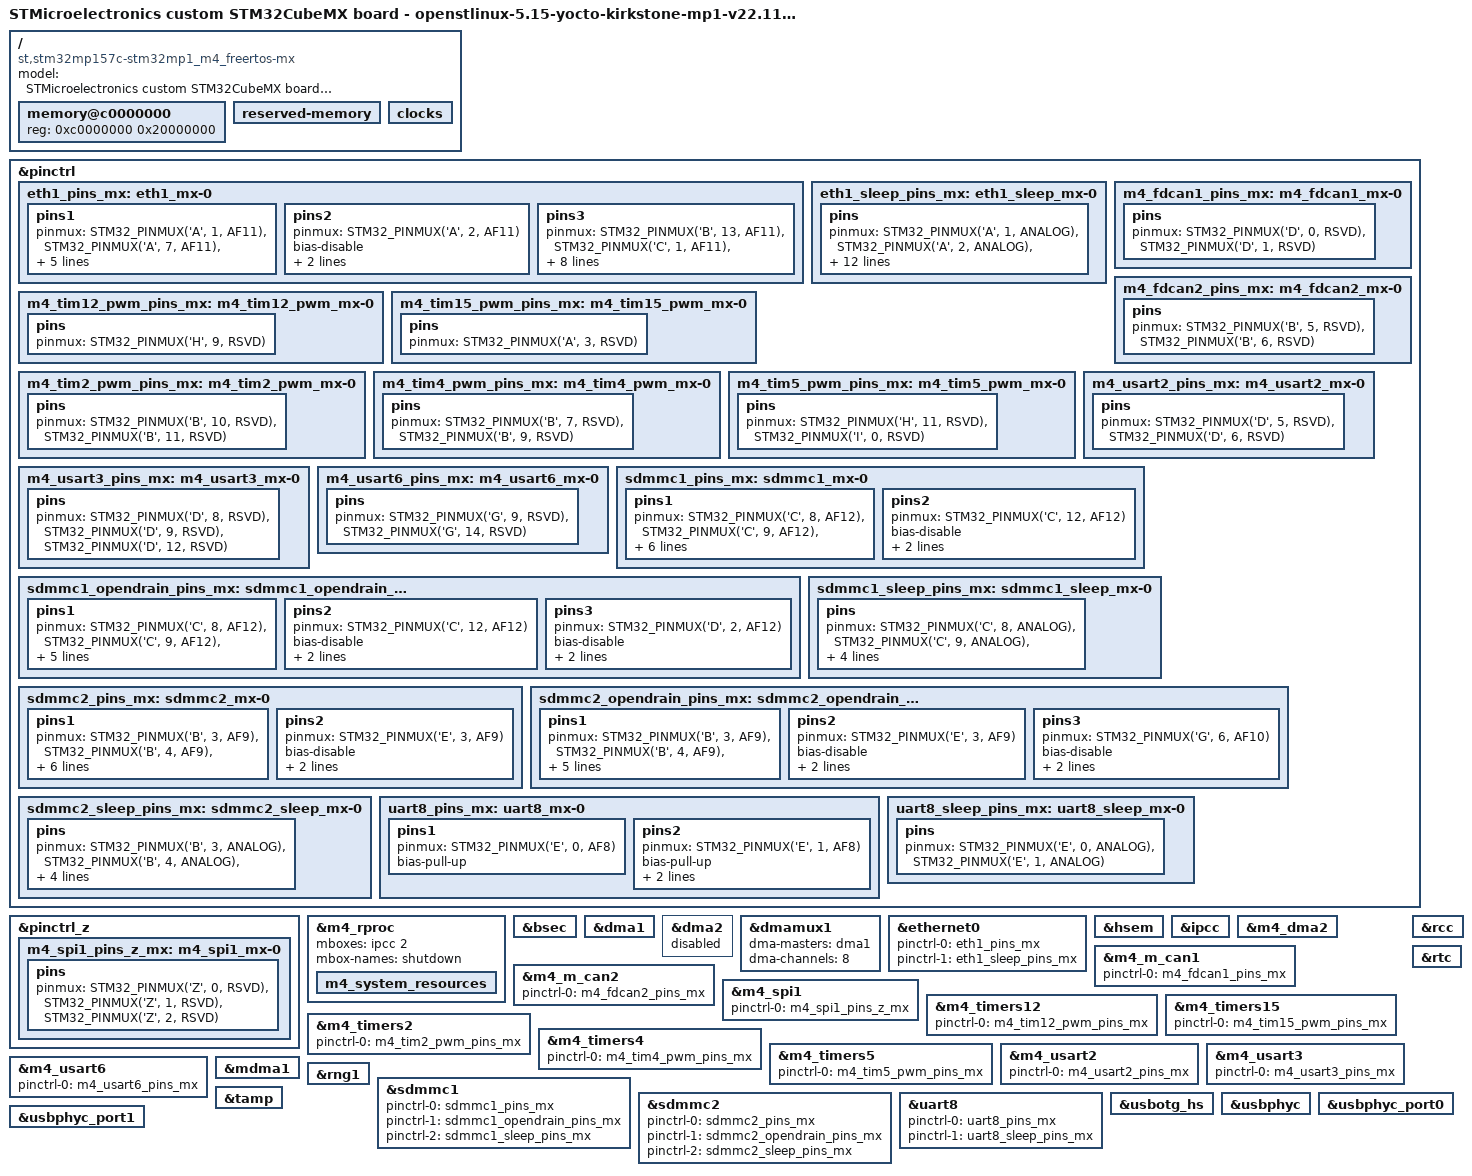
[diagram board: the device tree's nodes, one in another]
/* SPDX-License-Identifier: (GPL-2.0+ OR BSD-3-Clause) */
/*
 * Copyright (C) STMicroelectronics 2023 - All Rights Reserved
 * Author: STM32CubeMX code generation for STMicroelectronics.
 */

/* For more information on Device Tree configuration, please refer to
 * https://wiki.st.com/stm32mpu/wiki/Category:Device_tree_configuration
 */

/dts-v1/;
#include <dt-bindings/pinctrl/stm32-pinfunc.h>

#include "stm32mp157.dtsi"
#include "stm32mp15xc.dtsi"
#include "stm32mp15xxac-pinctrl.dtsi"
#include "stm32mp15-m4-srm.dtsi"

/* USER CODE BEGIN includes */
/* USER CODE END includes */

/ {
	model = "STMicroelectronics custom STM32CubeMX board - openstlinux-5.15-yocto-kirkstone-mp1-v22.11.23";
	compatible = "st,stm32mp157c-stm32mp1_m4_freertos-mx", "st,stm32mp157";

	memory@c0000000 {
		device_type = "memory";
		reg = <0xc0000000 0x20000000>;

		/* USER CODE BEGIN memory */
		/* USER CODE END memory */
	};

	reserved-memory {
		#address-cells = <1>;
		#size-cells = <1>;
		ranges;

		/* USER CODE BEGIN reserved-memory */
		/* USER CODE END reserved-memory */
	};

	/* USER CODE BEGIN root */
	/* USER CODE END root */

	clocks {

		/* USER CODE BEGIN clocks */
		/* USER CODE END clocks */
	};

}; /*root*/

&pinctrl {

	eth1_pins_mx: eth1_mx-0 {
		pins1 {
			pinmux = <STM32_PINMUX('A', 1, AF11)>, /* ETH1_RX_CLK */
					 <STM32_PINMUX('A', 7, AF11)>, /* ETH1_RX_CTL */
					 <STM32_PINMUX('C', 4, AF11)>, /* ETH1_RXD0 */
					 <STM32_PINMUX('C', 5, AF11)>, /* ETH1_RXD1 */
					 <STM32_PINMUX('H', 6, AF11)>, /* ETH1_RXD2 */
					 <STM32_PINMUX('H', 7, AF11)>; /* ETH1_RXD3 */
			bias-disable;
		};
		pins2 {
			pinmux = <STM32_PINMUX('A', 2, AF11)>; /* ETH1_MDIO */
			bias-disable;
			drive-push-pull;
			slew-rate = <0>;
		};
		pins3 {
			pinmux = <STM32_PINMUX('B', 13, AF11)>, /* ETH1_TXD1 */
					 <STM32_PINMUX('C', 1, AF11)>, /* ETH1_MDC */
					 <STM32_PINMUX('C', 2, AF11)>, /* ETH1_TXD2 */
					 <STM32_PINMUX('E', 2, AF11)>, /* ETH1_TXD3 */
					 <STM32_PINMUX('G', 4, AF11)>, /* ETH1_GTX_CLK */
					 <STM32_PINMUX('G', 11, AF11)>, /* ETH1_TX_CTL */
					 <STM32_PINMUX('G', 13, AF11)>; /* ETH1_TXD0 */
			bias-disable;
			drive-push-pull;
			slew-rate = <2>;
		};
	};

	eth1_sleep_pins_mx: eth1_sleep_mx-0 {
		pins {
			pinmux = <STM32_PINMUX('A', 1, ANALOG)>, /* ETH1_RX_CLK */
					 <STM32_PINMUX('A', 2, ANALOG)>, /* ETH1_MDIO */
					 <STM32_PINMUX('A', 7, ANALOG)>, /* ETH1_RX_CTL */
					 <STM32_PINMUX('B', 13, ANALOG)>, /* ETH1_TXD1 */
					 <STM32_PINMUX('C', 1, ANALOG)>, /* ETH1_MDC */
					 <STM32_PINMUX('C', 2, ANALOG)>, /* ETH1_TXD2 */
					 <STM32_PINMUX('C', 4, ANALOG)>, /* ETH1_RXD0 */
					 <STM32_PINMUX('C', 5, ANALOG)>, /* ETH1_RXD1 */
					 <STM32_PINMUX('E', 2, ANALOG)>, /* ETH1_TXD3 */
					 <STM32_PINMUX('G', 4, ANALOG)>, /* ETH1_GTX_CLK */
					 <STM32_PINMUX('G', 11, ANALOG)>, /* ETH1_TX_CTL */
					 <STM32_PINMUX('G', 13, ANALOG)>, /* ETH1_TXD0 */
					 <STM32_PINMUX('H', 6, ANALOG)>, /* ETH1_RXD2 */
					 <STM32_PINMUX('H', 7, ANALOG)>; /* ETH1_RXD3 */
		};
	};

	m4_fdcan1_pins_mx: m4_fdcan1_mx-0 {
		pins {
			pinmux = <STM32_PINMUX('D', 0, RSVD)>, /* FDCAN1_RX */
					 <STM32_PINMUX('D', 1, RSVD)>; /* FDCAN1_TX */
		};
	};

	m4_fdcan2_pins_mx: m4_fdcan2_mx-0 {
		pins {
			pinmux = <STM32_PINMUX('B', 5, RSVD)>, /* FDCAN2_RX */
					 <STM32_PINMUX('B', 6, RSVD)>; /* FDCAN2_TX */
		};
	};

	m4_tim12_pwm_pins_mx: m4_tim12_pwm_mx-0 {
		pins {
			pinmux = <STM32_PINMUX('H', 9, RSVD)>; /* TIM12_CH2 */
		};
	};

	m4_tim15_pwm_pins_mx: m4_tim15_pwm_mx-0 {
		pins {
			pinmux = <STM32_PINMUX('A', 3, RSVD)>; /* TIM15_CH2 */
		};
	};

	m4_tim2_pwm_pins_mx: m4_tim2_pwm_mx-0 {
		pins {
			pinmux = <STM32_PINMUX('B', 10, RSVD)>, /* TIM2_CH3 */
					 <STM32_PINMUX('B', 11, RSVD)>; /* TIM2_CH4 */
		};
	};

	m4_tim4_pwm_pins_mx: m4_tim4_pwm_mx-0 {
		pins {
			pinmux = <STM32_PINMUX('B', 7, RSVD)>, /* TIM4_CH2 */
					 <STM32_PINMUX('B', 9, RSVD)>; /* TIM4_CH4 */
		};
	};

	m4_tim5_pwm_pins_mx: m4_tim5_pwm_mx-0 {
		pins {
			pinmux = <STM32_PINMUX('H', 11, RSVD)>, /* TIM5_CH2 */
					 <STM32_PINMUX('I', 0, RSVD)>; /* TIM5_CH4 */
		};
	};

	m4_usart2_pins_mx: m4_usart2_mx-0 {
		pins {
			pinmux = <STM32_PINMUX('D', 5, RSVD)>, /* USART2_TX */
					 <STM32_PINMUX('D', 6, RSVD)>; /* USART2_RX */
		};
	};

	m4_usart3_pins_mx: m4_usart3_mx-0 {
		pins {
			pinmux = <STM32_PINMUX('D', 8, RSVD)>, /* USART3_TX */
					 <STM32_PINMUX('D', 9, RSVD)>, /* USART3_RX */
					 <STM32_PINMUX('D', 12, RSVD)>; /* USART3_DE */
		};
	};

	m4_usart6_pins_mx: m4_usart6_mx-0 {
		pins {
			pinmux = <STM32_PINMUX('G', 9, RSVD)>, /* USART6_RX */
					 <STM32_PINMUX('G', 14, RSVD)>; /* USART6_TX */
		};
	};

	sdmmc1_pins_mx: sdmmc1_mx-0 {
		pins1 {
			pinmux = <STM32_PINMUX('C', 8, AF12)>, /* SDMMC1_D0 */
					 <STM32_PINMUX('C', 9, AF12)>, /* SDMMC1_D1 */
					 <STM32_PINMUX('C', 10, AF12)>, /* SDMMC1_D2 */
					 <STM32_PINMUX('C', 11, AF12)>, /* SDMMC1_D3 */
					 <STM32_PINMUX('D', 2, AF12)>; /* SDMMC1_CMD */
			bias-disable;
			drive-push-pull;
			slew-rate = <1>;
		};
		pins2 {
			pinmux = <STM32_PINMUX('C', 12, AF12)>; /* SDMMC1_CK */
			bias-disable;
			drive-push-pull;
			slew-rate = <3>;
		};
	};

	sdmmc1_opendrain_pins_mx: sdmmc1_opendrain_mx-0 {
		pins1 {
			pinmux = <STM32_PINMUX('C', 8, AF12)>, /* SDMMC1_D0 */
					 <STM32_PINMUX('C', 9, AF12)>, /* SDMMC1_D1 */
					 <STM32_PINMUX('C', 10, AF12)>, /* SDMMC1_D2 */
					 <STM32_PINMUX('C', 11, AF12)>; /* SDMMC1_D3 */
			bias-disable;
			drive-push-pull;
			slew-rate = <1>;
		};
		pins2 {
			pinmux = <STM32_PINMUX('C', 12, AF12)>; /* SDMMC1_CK */
			bias-disable;
			drive-push-pull;
			slew-rate = <3>;
		};
		pins3 {
			pinmux = <STM32_PINMUX('D', 2, AF12)>; /* SDMMC1_CMD */
			bias-disable;
			drive-open-drain;
			slew-rate = <1>;
		};
	};

	sdmmc1_sleep_pins_mx: sdmmc1_sleep_mx-0 {
		pins {
			pinmux = <STM32_PINMUX('C', 8, ANALOG)>, /* SDMMC1_D0 */
					 <STM32_PINMUX('C', 9, ANALOG)>, /* SDMMC1_D1 */
					 <STM32_PINMUX('C', 10, ANALOG)>, /* SDMMC1_D2 */
					 <STM32_PINMUX('C', 11, ANALOG)>, /* SDMMC1_D3 */
					 <STM32_PINMUX('C', 12, ANALOG)>, /* SDMMC1_CK */
					 <STM32_PINMUX('D', 2, ANALOG)>; /* SDMMC1_CMD */
		};
	};

	sdmmc2_pins_mx: sdmmc2_mx-0 {
		pins1 {
			pinmux = <STM32_PINMUX('B', 3, AF9)>, /* SDMMC2_D2 */
					 <STM32_PINMUX('B', 4, AF9)>, /* SDMMC2_D3 */
					 <STM32_PINMUX('B', 14, AF9)>, /* SDMMC2_D0 */
					 <STM32_PINMUX('B', 15, AF9)>, /* SDMMC2_D1 */
					 <STM32_PINMUX('G', 6, AF10)>; /* SDMMC2_CMD */
			bias-disable;
			drive-push-pull;
			slew-rate = <1>;
		};
		pins2 {
			pinmux = <STM32_PINMUX('E', 3, AF9)>; /* SDMMC2_CK */
			bias-disable;
			drive-push-pull;
			slew-rate = <3>;
		};
	};

	sdmmc2_opendrain_pins_mx: sdmmc2_opendrain_mx-0 {
		pins1 {
			pinmux = <STM32_PINMUX('B', 3, AF9)>, /* SDMMC2_D2 */
					 <STM32_PINMUX('B', 4, AF9)>, /* SDMMC2_D3 */
					 <STM32_PINMUX('B', 14, AF9)>, /* SDMMC2_D0 */
					 <STM32_PINMUX('B', 15, AF9)>; /* SDMMC2_D1 */
			bias-disable;
			drive-push-pull;
			slew-rate = <1>;
		};
		pins2 {
			pinmux = <STM32_PINMUX('E', 3, AF9)>; /* SDMMC2_CK */
			bias-disable;
			drive-push-pull;
			slew-rate = <3>;
		};
		pins3 {
			pinmux = <STM32_PINMUX('G', 6, AF10)>; /* SDMMC2_CMD */
			bias-disable;
			drive-open-drain;
			slew-rate = <1>;
		};
	};

	sdmmc2_sleep_pins_mx: sdmmc2_sleep_mx-0 {
		pins {
			pinmux = <STM32_PINMUX('B', 3, ANALOG)>, /* SDMMC2_D2 */
					 <STM32_PINMUX('B', 4, ANALOG)>, /* SDMMC2_D3 */
					 <STM32_PINMUX('B', 14, ANALOG)>, /* SDMMC2_D0 */
					 <STM32_PINMUX('B', 15, ANALOG)>, /* SDMMC2_D1 */
					 <STM32_PINMUX('E', 3, ANALOG)>, /* SDMMC2_CK */
					 <STM32_PINMUX('G', 6, ANALOG)>; /* SDMMC2_CMD */
		};
	};

	uart8_pins_mx: uart8_mx-0 {
		pins1 {
			pinmux = <STM32_PINMUX('E', 0, AF8)>; /* UART8_RX */
			bias-pull-up;
		};
		pins2 {
			pinmux = <STM32_PINMUX('E', 1, AF8)>; /* UART8_TX */
			bias-pull-up;
			drive-push-pull;
			slew-rate = <2>;
		};
	};

	uart8_sleep_pins_mx: uart8_sleep_mx-0 {
		pins {
			pinmux = <STM32_PINMUX('E', 0, ANALOG)>, /* UART8_RX */
					 <STM32_PINMUX('E', 1, ANALOG)>; /* UART8_TX */
		};
	};

	/* USER CODE BEGIN pinctrl */
	/* USER CODE END pinctrl */
};

&pinctrl_z {

	m4_spi1_pins_z_mx: m4_spi1_mx-0 {
		pins {
			pinmux = <STM32_PINMUX('Z', 0, RSVD)>, /* SPI1_SCK */
					 <STM32_PINMUX('Z', 1, RSVD)>, /* SPI1_MISO */
					 <STM32_PINMUX('Z', 2, RSVD)>; /* SPI1_MOSI */
		};
	};

	/* USER CODE BEGIN pinctrl_z */
	/* USER CODE END pinctrl_z */
};

&m4_rproc{
	/*Restriction: "memory-region" property is not managed - please to use User-Section if needed*/
	mboxes = <&ipcc 2>;
	mbox-names = "shutdown";
	status = "okay";

	/* USER CODE BEGIN m4_rproc */
	/* USER CODE END m4_rproc */

	m4_system_resources{
		status = "okay";

		/* USER CODE BEGIN m4_system_resources */
		/* USER CODE END m4_system_resources */
	};
};

&bsec{
	status = "okay";

	/* USER CODE BEGIN bsec */
	/* USER CODE END bsec */
};

&dma1{
	status = "okay";

	/* USER CODE BEGIN dma1 */
	/* USER CODE END dma1 */
};

&dma2{
	status = "disabled";

	/* USER CODE BEGIN dma2 */
	/* USER CODE END dma2 */
};

&dmamux1{
	status = "okay";

	dma-masters = <&dma1>;
	dma-channels = <8>;

	/* USER CODE BEGIN dmamux1 */
	/* USER CODE END dmamux1 */
};

&ethernet0{
	pinctrl-names = "default", "sleep";
	pinctrl-0 = <&eth1_pins_mx>;
	pinctrl-1 = <&eth1_sleep_pins_mx>;
	status = "okay";

	/* USER CODE BEGIN ethernet0 */
	/* USER CODE END ethernet0 */
};

&hsem{
	status = "okay";

	/* USER CODE BEGIN hsem */
	/* USER CODE END hsem */
};

&ipcc{
	status = "okay";

	/* USER CODE BEGIN ipcc */
	/* USER CODE END ipcc */
};

&m4_dma2{
	status = "okay";

	/* USER CODE BEGIN m4_dma2 */
	/* USER CODE END m4_dma2 */
};

&m4_m_can1{
	pinctrl-names = "default";
	pinctrl-0 = <&m4_fdcan1_pins_mx>;
	status = "okay";

	/* USER CODE BEGIN m4_m_can1 */
	/* USER CODE END m4_m_can1 */
};

&m4_m_can2{
	pinctrl-names = "default";
	pinctrl-0 = <&m4_fdcan2_pins_mx>;
	status = "okay";

	/* USER CODE BEGIN m4_m_can2 */
	/* USER CODE END m4_m_can2 */
};

&m4_spi1{
	pinctrl-names = "default";
	pinctrl-0 = <&m4_spi1_pins_z_mx>;
	status = "okay";

	/* USER CODE BEGIN m4_spi1 */
	/* USER CODE END m4_spi1 */
};

&m4_timers12{
	pinctrl-names = "default";
	pinctrl-0 = <&m4_tim12_pwm_pins_mx>;
	status = "okay";

	/* USER CODE BEGIN m4_timers12 */
	/* USER CODE END m4_timers12 */
};

&m4_timers15{
	pinctrl-names = "default";
	pinctrl-0 = <&m4_tim15_pwm_pins_mx>;
	status = "okay";

	/* USER CODE BEGIN m4_timers15 */
	/* USER CODE END m4_timers15 */
};

&m4_timers2{
	pinctrl-names = "default";
	pinctrl-0 = <&m4_tim2_pwm_pins_mx>;
	status = "okay";

	/* USER CODE BEGIN m4_timers2 */
	/* USER CODE END m4_timers2 */
};

&m4_timers4{
	pinctrl-names = "default";
	pinctrl-0 = <&m4_tim4_pwm_pins_mx>;
	status = "okay";

	/* USER CODE BEGIN m4_timers4 */
	/* USER CODE END m4_timers4 */
};

&m4_timers5{
	pinctrl-names = "default";
	pinctrl-0 = <&m4_tim5_pwm_pins_mx>;
	status = "okay";

	/* USER CODE BEGIN m4_timers5 */
	/* USER CODE END m4_timers5 */
};

&m4_usart2{
	pinctrl-names = "default";
	pinctrl-0 = <&m4_usart2_pins_mx>;
	status = "okay";

	/* USER CODE BEGIN m4_usart2 */
	/* USER CODE END m4_usart2 */
};

&m4_usart3{
	pinctrl-names = "default";
	pinctrl-0 = <&m4_usart3_pins_mx>;
	status = "okay";

	/* USER CODE BEGIN m4_usart3 */
	/* USER CODE END m4_usart3 */
};

&m4_usart6{
	pinctrl-names = "default";
	pinctrl-0 = <&m4_usart6_pins_mx>;
	status = "okay";

	/* USER CODE BEGIN m4_usart6 */
	/* USER CODE END m4_usart6 */
};

&mdma1{
	status = "okay";

	/* USER CODE BEGIN mdma1 */
	/* USER CODE END mdma1 */
};

&rcc{
	status = "okay";

	/* USER CODE BEGIN rcc */
	/* USER CODE END rcc */
};

&rng1{
	status = "okay";

	/* USER CODE BEGIN rng1 */
	/* USER CODE END rng1 */
};

&rtc{
	status = "okay";

	/* USER CODE BEGIN rtc */
	/* USER CODE END rtc */
};

&sdmmc1{
	pinctrl-names = "default", "opendrain", "sleep";
	pinctrl-0 = <&sdmmc1_pins_mx>;
	pinctrl-1 = <&sdmmc1_opendrain_pins_mx>;
	pinctrl-2 = <&sdmmc1_sleep_pins_mx>;
	status = "okay";

	/* USER CODE BEGIN sdmmc1 */
	/* USER CODE END sdmmc1 */
};

&sdmmc2{
	pinctrl-names = "default", "opendrain", "sleep";
	pinctrl-0 = <&sdmmc2_pins_mx>;
	pinctrl-1 = <&sdmmc2_opendrain_pins_mx>;
	pinctrl-2 = <&sdmmc2_sleep_pins_mx>;
	status = "okay";

	/* USER CODE BEGIN sdmmc2 */
	/* USER CODE END sdmmc2 */
};

&tamp{
	status = "okay";

	/* USER CODE BEGIN tamp */
	/* USER CODE END tamp */
};

&uart8{
	pinctrl-names = "default", "sleep";
	pinctrl-0 = <&uart8_pins_mx>;
	pinctrl-1 = <&uart8_sleep_pins_mx>;
	status = "okay";

	/* USER CODE BEGIN uart8 */
	/* USER CODE END uart8 */
};

&usbotg_hs{
	status = "okay";

	/* USER CODE BEGIN usbotg_hs */
	/* USER CODE END usbotg_hs */
};

&usbphyc{
	status = "okay";

	/* USER CODE BEGIN usbphyc */
	/* USER CODE END usbphyc */
};

&usbphyc_port0{
	status = "okay";

	/* USER CODE BEGIN usbphyc_port0 */
	/* USER CODE END usbphyc_port0 */
};

&usbphyc_port1{
	status = "okay";

	/* USER CODE BEGIN usbphyc_port1 */
	/* USER CODE END usbphyc_port1 */
};

/* USER CODE BEGIN addons */
/* USER CODE END addons */

